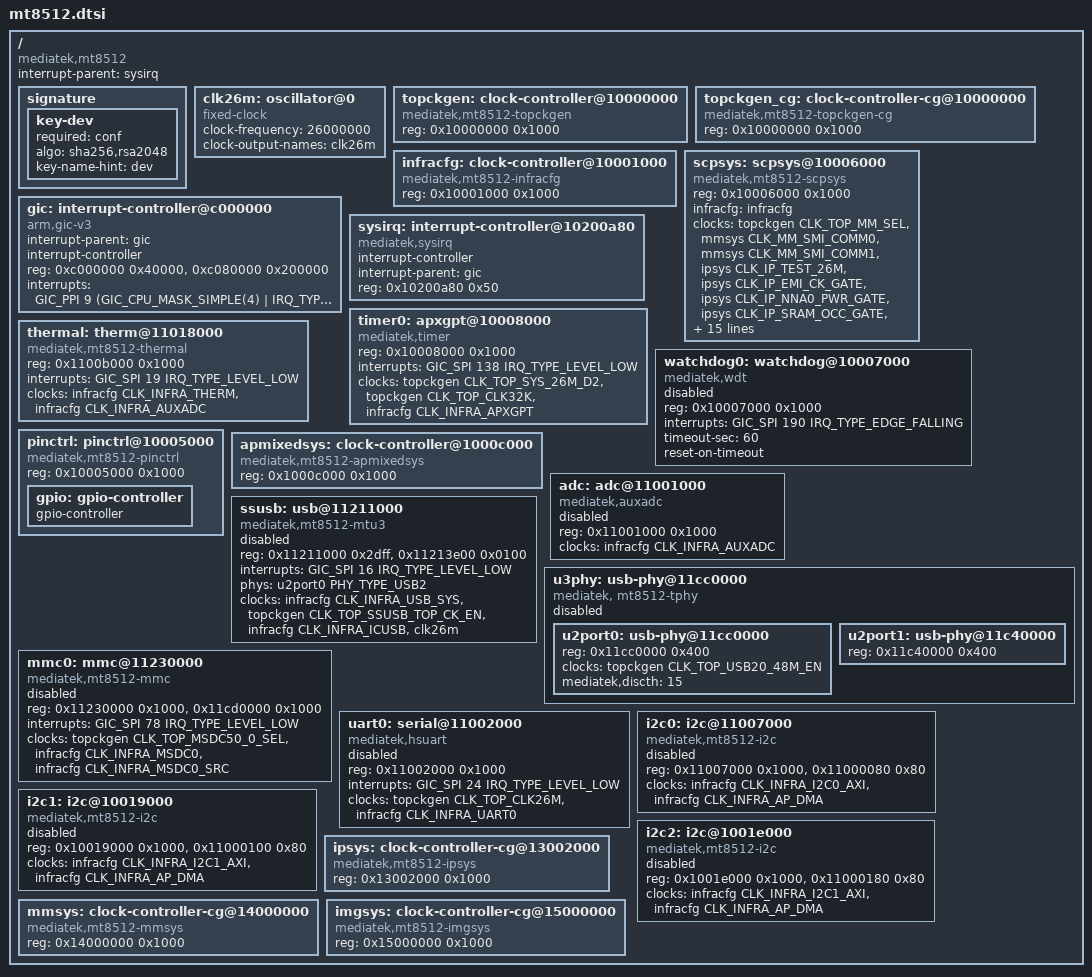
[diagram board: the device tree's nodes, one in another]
// SPDX-License-Identifier: (GPL-2.0 OR MIT)
/*
 * Copyright (C) 2019 MediaTek Inc.
 * Author: Mingming Lee <mingming.lee@mediatek.com>
 *
 */

#include <dt-bindings/clock/mt8512-clk.h>
#include <dt-bindings/gpio/gpio.h>
#include <dt-bindings/interrupt-controller/irq.h>
#include <dt-bindings/interrupt-controller/arm-gic.h>
#include <dt-bindings/power/mt8512-power.h>
#include <dt-bindings/phy/phy.h>

/ {
	compatible = "mediatek,mt8512";
	interrupt-parent = <&sysirq>;
	#address-cells = <1>;
	#size-cells = <1>;

	signature {
		key-dev {
			required = "conf";
			algo = "sha256,rsa2048";
			key-name-hint = "dev";
		};
	};

	clk26m: oscillator@0 {
		compatible = "fixed-clock";
		#clock-cells = <0>;
		clock-frequency = <26000000>;
		clock-output-names = "clk26m";
	};

	topckgen: clock-controller@10000000 {
		compatible = "mediatek,mt8512-topckgen";
		reg = <0x10000000 0x1000>;
		#clock-cells = <1>;
	};

	topckgen_cg: clock-controller-cg@10000000 {
		compatible = "mediatek,mt8512-topckgen-cg";
		reg = <0x10000000 0x1000>;
		#clock-cells = <1>;
	};

	infracfg: clock-controller@10001000 {
		compatible = "mediatek,mt8512-infracfg", "syscon";
		reg = <0x10001000 0x1000>;
		#clock-cells = <1>;
	};

	scpsys: scpsys@10006000 {
		compatible = "mediatek,mt8512-scpsys";
		#power-domain-cells = <1>;
		reg = <0x10006000 0x1000>;
		infracfg = <&infracfg>;
		clocks = <&topckgen CLK_TOP_MM_SEL>,
			 <&mmsys CLK_MM_SMI_COMM0>,
			 <&mmsys CLK_MM_SMI_COMM1>,
			 <&ipsys CLK_IP_TEST_26M>,
			 <&ipsys CLK_IP_EMI_CK_GATE>,
			 <&ipsys CLK_IP_NNA0_PWR_GATE>,
			 <&ipsys CLK_IP_SRAM_OCC_GATE>,
			 <&ipsys CLK_IP_HD_FAXI_CK>,
			 <&ipsys CLK_IP_NNA1_OCC_GATE>,
			 <&ipsys CLK_IP_NNA1_PWR_GATE>,
			 <&ipsys CLK_IP_WFST_OCC_GATE>,
			 <&ipsys CLK_IP_WFST_PWR_GATE>,
			 <&topckgen CLK_TOP_CONN_32K>,
			 <&topckgen CLK_TOP_CONN_26M>,
			 <&topckgen CLK_TOP_DSP_SEL>,
			 <&topckgen CLK_TOP_DSP_26M>,
			 <&topckgen CLK_TOP_SRAM_SEL>,
			 <&infracfg CLK_INFRA_DSP_AXI>,
			 <&topckgen CLK_TOP_A1SYS_SEL>,
			 <&infracfg CLK_INFRA_AUDIO>,
			 <&infracfg CLK_INFRA_AUD_ASRC>,
			 <&topckgen CLK_TOP_SSUSB_TOP_CK_EN>;
		clock-names = "mm", "mm-0", "mm-1",
			      "ipsys", "ip0-0", "ip0-1",
			      "ip0-2", "ip0-3", "ip1-0",
			      "ip1-1", "ip2-0", "ip2-1",
			      "conn", "conn1", "dsp",
			      "dsp1", "dsp-0", "dsp-1",
			      "audafe", "audafe-0", "audsrc", "usb";
	};

	gic: interrupt-controller@c000000 {
		 compatible = "arm,gic-v3";
		#interrupt-cells = <3>;
		interrupt-parent = <&gic>;
		interrupt-controller;
		reg = <0xc000000 0x40000>,	/* GICD */
			  <0xc080000 0x200000>; /* GICR */
		interrupts = <GIC_PPI 9
			(GIC_CPU_MASK_SIMPLE(4) | IRQ_TYPE_LEVEL_HIGH)>;
	};

	sysirq: interrupt-controller@10200a80 {
		compatible = "mediatek,sysirq";
		interrupt-controller;
		#interrupt-cells = <3>;
		interrupt-parent = <&gic>;
		reg = <0x10200a80 0x50>;
	};

	timer0: apxgpt@10008000 {
		compatible = "mediatek,timer";
		reg = <0x10008000 0x1000>;
		interrupts = <GIC_SPI 138 IRQ_TYPE_LEVEL_LOW>;
		clocks = <&topckgen CLK_TOP_SYS_26M_D2>,
			 <&topckgen CLK_TOP_CLK32K>,
			 <&infracfg CLK_INFRA_APXGPT>;
		clock-names = "clk13m",
			 "clk32k",
			 "bus";
	};

	thermal: therm@11018000 {
		compatible = "mediatek,mt8512-thermal";
		reg = <0x1100b000 0x1000>;
		interrupts = <GIC_SPI 19 IRQ_TYPE_LEVEL_LOW>;
		clocks = <&infracfg CLK_INFRA_THERM>,
			<&infracfg CLK_INFRA_AUXADC>;
		clock-names = "therm", "auxadc";
		status = "okay";
	};

	watchdog0: watchdog@10007000 {
		compatible = "mediatek,wdt";
		reg = <0x10007000 0x1000>;
		interrupts = <GIC_SPI 190 IRQ_TYPE_EDGE_FALLING>;
		#reset-cells = <1>;
		status = "disabled";
		timeout-sec = <60>;
		reset-on-timeout;
	};

	pinctrl: pinctrl@10005000 {
		compatible = "mediatek,mt8512-pinctrl";
		reg = <0x10005000 0x1000>;
		gpio: gpio-controller {
			gpio-controller;
			#gpio-cells = <2>;
		};
	};

	apmixedsys: clock-controller@1000c000 {
		compatible = "mediatek,mt8512-apmixedsys";
		reg = <0x1000c000 0x1000>;
		#clock-cells = <1>;
	};

	adc: adc@11001000 {
		compatible = "mediatek,auxadc";
		reg = <0x11001000 0x1000>;
		clocks = <&infracfg CLK_INFRA_AUXADC>;
		clock-names = "main";
		#io-channel-cells = <1>;
		status = "disabled";
	};

	ssusb: usb@11211000 {
		compatible = "mediatek,mt8512-mtu3", "mediatek,mtu3";
		reg = <0x11211000 0x2dff>,
		      <0x11213e00 0x0100>;
		reg-names = "mac", "ippc";
		interrupts = <GIC_SPI 16 IRQ_TYPE_LEVEL_LOW>;
		phys = <&u2port0 PHY_TYPE_USB2>;
		//power-domains = <&scpsys MT8512_POWER_DOMAIN_USB>;
		clocks = <&infracfg CLK_INFRA_USB_SYS>,
			 <&topckgen CLK_TOP_SSUSB_TOP_CK_EN>,
			 //<&topckgen_cg CLK_TOP_SSUSB_TOP_CK_EN>,
			 <&infracfg CLK_INFRA_ICUSB>,
			 <&clk26m>;
		clock-names = "sys_ck", "ref_ck", "mcu_ck", "dma_ck";
		status = "disabled";
	};

	u3phy: usb-phy@11cc0000 {
		compatible = "mediatek, mt8512-tphy",
			     "mediatek,generic-tphy-v2";
		#address-cells = <1>;
		#size-cells = <1>;
		ranges;
		status = "disabled";

		u2port0: usb-phy@11cc0000 {
			reg = <0x11cc0000 0x400>;
			clocks = <&topckgen CLK_TOP_USB20_48M_EN>;
			//clocks = <&topckgen_cg CLK_TOP_USB20_48M_EN>;
			clock-names = "ref";
			#phy-cells = <1>;
			mediatek,discth = <15>;
			status = "okay";
		};

		u2port1: usb-phy@11c40000 {
			reg = <0x11c40000 0x400>;
			//clocks = <&clk26m>;
			//clock-names = "ref";
			#phy-cells = <1>;
			status = "okay";
		};
	};
	mmc0: mmc@11230000 {
		compatible = "mediatek,mt8512-mmc";
		reg = <0x11230000 0x1000>,
		      <0x11cd0000 0x1000>;
		interrupts = <GIC_SPI 78 IRQ_TYPE_LEVEL_LOW>;
		clocks = <&topckgen CLK_TOP_MSDC50_0_SEL>,
			 <&infracfg CLK_INFRA_MSDC0>,
			 <&infracfg CLK_INFRA_MSDC0_SRC>;
		clock-names = "source", "hclk", "source_cg";
		status = "disabled";
	};

	uart0: serial@11002000 {
		compatible = "mediatek,hsuart";
		reg = <0x11002000 0x1000>;
		interrupts = <GIC_SPI 24 IRQ_TYPE_LEVEL_LOW>;
		clocks = <&topckgen CLK_TOP_CLK26M>,
			<&infracfg CLK_INFRA_UART0>;
		clock-names = "baud", "bus";
		status = "disabled";
	};

	i2c0: i2c@11007000 {
		compatible = "mediatek,mt8512-i2c";
		reg = <0x11007000 0x1000>,
			  <0x11000080 0x80>;
		clocks = <&infracfg CLK_INFRA_I2C0_AXI>,
					<&infracfg CLK_INFRA_AP_DMA>;
		clock-names = "main", "dma";
		#address-cells = <1>;
		#size-cells = <0>;
		status = "disabled";
	};

	i2c1: i2c@10019000 {
		compatible = "mediatek,mt8512-i2c";
		reg = <0x10019000 0x1000>,
			  <0x11000100 0x80>;
		clocks = <&infracfg CLK_INFRA_I2C1_AXI>,
				<&infracfg CLK_INFRA_AP_DMA>;
		clock-names = "main", "dma";
		#address-cells = <1>;
		#size-cells = <0>;
		status = "disabled";
	};

	i2c2: i2c@1001e000 {
		compatible = "mediatek,mt8512-i2c";
		reg = <0x1001e000 0x1000>,
			  <0x11000180 0x80>;
		clocks = <&infracfg CLK_INFRA_I2C1_AXI>,
					<&infracfg CLK_INFRA_AP_DMA>;
		clock-names = "main", "dma";
		#address-cells = <1>;
		#size-cells = <0>;
		status = "disabled";
	};

	ipsys: clock-controller-cg@13002000 {
		compatible = "mediatek,mt8512-ipsys";
		reg = <0x13002000 0x1000>;
		#clock-cells = <1>;
	};

	mmsys: clock-controller-cg@14000000 {
		compatible = "mediatek,mt8512-mmsys";
		reg = <0x14000000 0x1000>;
		#clock-cells = <1>;
	};

	imgsys: clock-controller-cg@15000000 {
		compatible = "mediatek,mt8512-imgsys";
		reg = <0x15000000 0x1000>;
		#clock-cells = <1>;
	};
};
